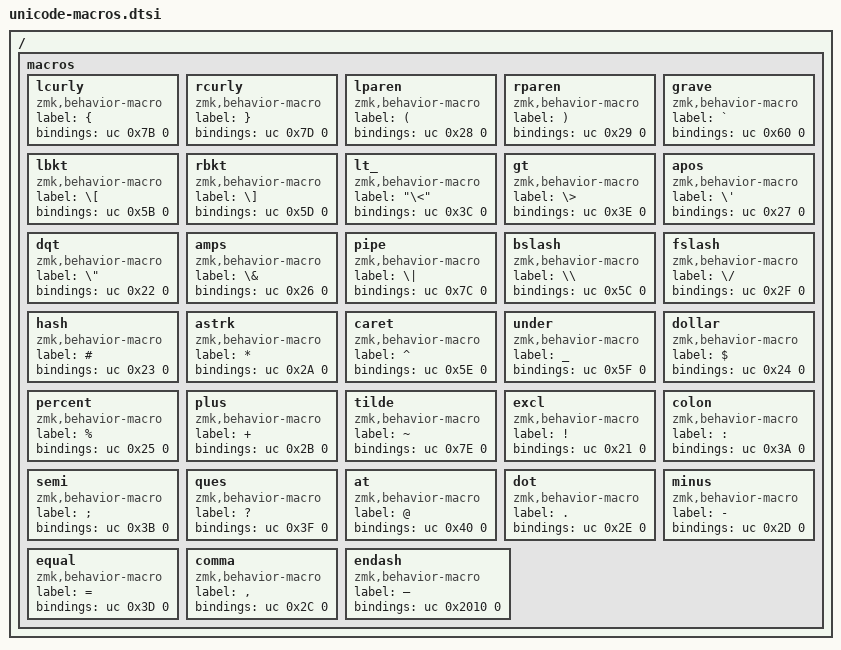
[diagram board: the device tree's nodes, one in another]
/ {
    macros {
        lcurly: lcurly {
            compatible = "zmk,behavior-macro";
            label = "{";
            #binding-cells = <0>;
            bindings = <&uc 0x7B 0>;
        };

        rcurly: rcurly {
            compatible = "zmk,behavior-macro";
            label = "}";
            #binding-cells = <0>;
            bindings = <&uc 0x7D 0>;
        };

        lparen: lparen {
            compatible = "zmk,behavior-macro";
            label = "(";
            #binding-cells = <0>;
            bindings = <&uc 0x28 0>;
        };

        rparen: rparen {
            compatible = "zmk,behavior-macro";
            label = ")";
            #binding-cells = <0>;
            bindings = <&uc 0x29 0>;
        };

        grave: grave {
            compatible = "zmk,behavior-macro";
            label = "`";
            #binding-cells = <0>;
            bindings = <&uc 0x60 0>;
        };

        lbkt: lbkt {
            compatible = "zmk,behavior-macro";
            label = "\[";
            #binding-cells = <0>;
            bindings = <&uc 0x5B 0>;
        };

        rbkt: rbkt {
            compatible = "zmk,behavior-macro";
            label = "\]";
            #binding-cells = <0>;
            bindings = <&uc 0x5D 0>;
        };

        lt_: lt_ {
            compatible = "zmk,behavior-macro";
            label = "\<";
            #binding-cells = <0>;
            bindings = <&uc 0x3C 0>;
        };

        gt: gt {
            compatible = "zmk,behavior-macro";
            label = "\>";
            #binding-cells = <0>;
            bindings = <&uc 0x3E 0>;
        };

        apos: apos {
            compatible = "zmk,behavior-macro";
            label = "\'";
            #binding-cells = <0>;
            bindings = <&uc 0x27 0>;
        };

        dqt: dqt {
            compatible = "zmk,behavior-macro";
            label = "\"";
            #binding-cells = <0>;
            bindings = <&uc 0x22 0>;
        };

        amps: amps {
            compatible = "zmk,behavior-macro";
            label = "\&";
            #binding-cells = <0>;
            bindings = <&uc 0x26 0>;
        };

        pipe: pipe {
            compatible = "zmk,behavior-macro";
            label = "\|";
            #binding-cells = <0>;
            bindings = <&uc 0x7C 0>;
        };

        bslash: bslash {
            compatible = "zmk,behavior-macro";
            label = "\\";
            #binding-cells = <0>;
            bindings = <&uc 0x5C 0>;
        };

        fslash: fslash {
            compatible = "zmk,behavior-macro";
            label = "\/";
            #binding-cells = <0>;
            bindings = <&uc 0x2F 0>;
        };

        hash: hash {
            compatible = "zmk,behavior-macro";
            label = "#";
            #binding-cells = <0>;
            bindings = <&uc 0x23 0>;
        };

        astrk: astrk {
            compatible = "zmk,behavior-macro";
            label = "*";
            #binding-cells = <0>;
            bindings = <&uc 0x2A 0>;
        };

        caret: caret {
            compatible = "zmk,behavior-macro";
            label = "^";
            #binding-cells = <0>;
            bindings = <&uc 0x5E 0>;
        };

        under: under {
            compatible = "zmk,behavior-macro";
            label = "_";
            #binding-cells = <0>;
            bindings = <&uc 0x5F 0>;
        };

        dollar: dollar {
            compatible = "zmk,behavior-macro";
            label = "$";
            #binding-cells = <0>;
            bindings = <&uc 0x24 0>;
        };

        percent: percent {
            compatible = "zmk,behavior-macro";
            label = "%";
            #binding-cells = <0>;
            bindings = <&uc 0x25 0>;
        };

        plus: plus {
            compatible = "zmk,behavior-macro";
            label = "+";
            #binding-cells = <0>;
            bindings = <&uc 0x2B 0>;
        };

        tilde: tilde {
            compatible = "zmk,behavior-macro";
            label = "~";
            #binding-cells = <0>;
            bindings = <&uc 0x7E 0>;
        };

        excl: excl {
            compatible = "zmk,behavior-macro";
            label = "!";
            #binding-cells = <0>;
            bindings = <&uc 0x21 0>;
        };

        colon: colon {
            compatible = "zmk,behavior-macro";
            label = ":";
            #binding-cells = <0>;
            bindings = <&uc 0x3A 0>;
        };

        semi: semi {
            compatible = "zmk,behavior-macro";
            label = ";";
            #binding-cells = <0>;
            bindings = <&uc 0x3B 0>;
        };

        ques: ques {
            compatible = "zmk,behavior-macro";
            label = "?";
            #binding-cells = <0>;
            bindings = <&uc 0x3F 0>;
        };

        at: at {
            compatible = "zmk,behavior-macro";
            label = "@";
            #binding-cells = <0>;
            bindings = <&uc 0x40 0>;
        };

        dot: dot {
            compatible = "zmk,behavior-macro";
            label = ".";
            #binding-cells = <0>;
            bindings = <&uc 0x2E 0>;
        };

        minus: minus {
            compatible = "zmk,behavior-macro";
            label = "-";
            #binding-cells = <0>;
            bindings = <&uc 0x2D 0>;
        };

        equal: equal {
            compatible = "zmk,behavior-macro";
            label = "=";
            #binding-cells = <0>;
            bindings = <&uc 0x3D 0>;
        };

        comma: comma {
            compatible = "zmk,behavior-macro";
            label = ",";
            #binding-cells = <0>;
            bindings = <&uc 0x2C 0>;
        };

        endash: endash {          // 0x2010 — en dash
            compatible = "zmk,behavior-macro";
            label = "–";
            #binding-cells = <0>;
            bindings = <&uc 0x2010 0>;
        };
    };
};
